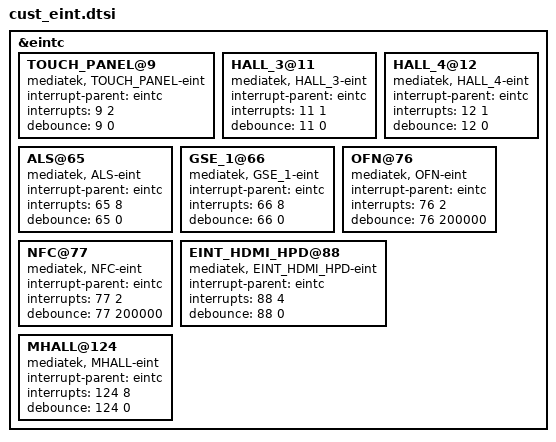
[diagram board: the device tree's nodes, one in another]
/*
 * Generated by MTK SP DrvGen Version 03.13.6 for MT6735M. Copyright MediaTek Inc. (C) 2013.
 * Tue Sep 06 18:36:35 2016
 * Do Not Modify the File.
 */

/*************************
 * EINT DTSI File
*************************/

&eintc {
	TOUCH_PANEL@9 {
		compatible = "mediatek, TOUCH_PANEL-eint";
		interrupt-parent = <&eintc>;
		interrupts = <9 2>;
		debounce = <9 0>;
	};

	HALL_3@11 {
		compatible = "mediatek, HALL_3-eint";
		interrupt-parent = <&eintc>;
		interrupts = <11 1>;
		debounce = <11 0>;
	};

	HALL_4@12 {
		compatible = "mediatek, HALL_4-eint";
		interrupt-parent = <&eintc>;
		interrupts = <12 1>;
		debounce = <12 0>;
	};

	ALS@65 {
		compatible = "mediatek, ALS-eint";
		interrupt-parent = <&eintc>;
		interrupts = <65 8>;
		debounce = <65 0>;
	};

	GSE_1@66 {
		compatible = "mediatek, GSE_1-eint";
		interrupt-parent = <&eintc>;
		interrupts = <66 8>;
		debounce = <66 0>;
	};

	OFN@76 {
		compatible = "mediatek, OFN-eint";
		interrupt-parent = <&eintc>;
		interrupts = <76 2>;
		debounce = <76 200000>;
	};

	NFC@77 {
		compatible = "mediatek, NFC-eint";
		interrupt-parent = <&eintc>;
		interrupts = <77 2>;
		debounce = <77 200000>;
	};

	EINT_HDMI_HPD@88 {
		compatible = "mediatek, EINT_HDMI_HPD-eint";
		interrupt-parent = <&eintc>;
		interrupts = <88 4>;
		debounce = <88 0>;
	};

	MHALL@124 {
		compatible = "mediatek, MHALL-eint";
		interrupt-parent = <&eintc>;
		interrupts = <124 8>;
		debounce = <124 0>;
	};

};
